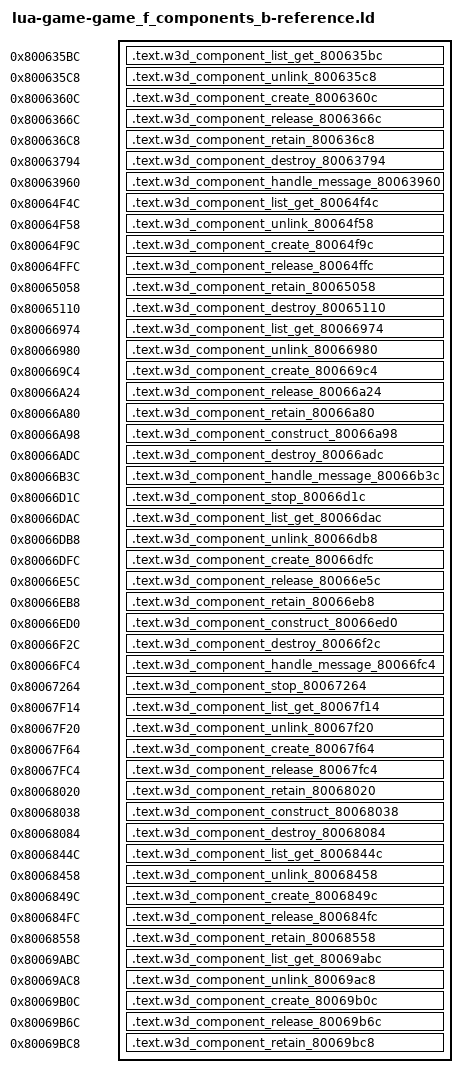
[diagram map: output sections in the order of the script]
/* Generated reference-only placements. All bodies are source-built. */
OUTPUT_FORMAT("elf32-powerpc")
OUTPUT_ARCH(powerpc)
ENTRY(w3d_component_list_get_800635bc)
_SDA_BASE_ = 0x804b2540;
_SDA2_BASE_ = 0x804c2540;
w3d_actor_base_destroy = 0x80161050;
w3d_actor_base_initialize = 0x80161014;
w3d_base_construct_8015fef0 = 0x8015fef0;
w3d_base_destroy_8015ff2c = 0x8015ff2c;
w3d_base_handle_message_8015fb34 = 0x8015fb34;
w3d_component_construct_800636e0 = 0x800636e0;
w3d_component_construct_80065070 = 0x80065070;
w3d_component_construct_80068570 = 0x80068570;
w3d_component_construct_80069c8c = 0x80069c8c;
w3d_component_destroy_80068648 = 0x80068648;
w3d_component_destroy_80069e94 = 0x80069e94;
w3d_component_list_80360300 = 0x80360300;
w3d_component_list_80360330 = 0x80360330;
w3d_component_list_80360360 = 0x80360360;
w3d_component_list_80360390 = 0x80360390;
w3d_component_list_803603c0 = 0x803603c0;
w3d_component_list_803603f0 = 0x803603f0;
w3d_component_list_80360420 = 0x80360420;
w3d_component_start_80063a0c = 0x80063a0c;
w3d_component_start_80066c9c = 0x80066c9c;
w3d_component_start_800670e0 = 0x800670e0;
w3d_component_stop_80064104 = 0x80064104;
w3d_component_vtable_8040edc0 = 0x8040edc0;
w3d_component_vtable_8040ee00 = 0x8040ee00;
w3d_component_vtable_8040ee40 = 0x8040ee40;
w3d_component_vtable_8040ee80 = 0x8040ee80;
w3d_component_vtable_8040eee8 = 0x8040eee8;
w3d_heap_allocate_entry_a = 0x801fe1d8;
w3d_owner_list_remove = 0x8020fd2c;
w3d_state_register = 0x8020fd04;
SECTIONS {
  .text.w3d_component_list_get_800635bc 0x800635bc : { *(.text.w3d_component_list_get_800635bc) }
  .text.w3d_component_unlink_800635c8 0x800635c8 : { *(.text.w3d_component_unlink_800635c8) }
  .text.w3d_component_create_8006360c 0x8006360c : { *(.text.w3d_component_create_8006360c) }
  .text.w3d_component_release_8006366c 0x8006366c : { *(.text.w3d_component_release_8006366c) }
  .text.w3d_component_retain_800636c8 0x800636c8 : { *(.text.w3d_component_retain_800636c8) }
  .text.w3d_component_destroy_80063794 0x80063794 : { *(.text.w3d_component_destroy_80063794) }
  .text.w3d_component_handle_message_80063960 0x80063960 : { *(.text.w3d_component_handle_message_80063960) }
  .text.w3d_component_list_get_80064f4c 0x80064f4c : { *(.text.w3d_component_list_get_80064f4c) }
  .text.w3d_component_unlink_80064f58 0x80064f58 : { *(.text.w3d_component_unlink_80064f58) }
  .text.w3d_component_create_80064f9c 0x80064f9c : { *(.text.w3d_component_create_80064f9c) }
  .text.w3d_component_release_80064ffc 0x80064ffc : { *(.text.w3d_component_release_80064ffc) }
  .text.w3d_component_retain_80065058 0x80065058 : { *(.text.w3d_component_retain_80065058) }
  .text.w3d_component_destroy_80065110 0x80065110 : { *(.text.w3d_component_destroy_80065110) }
  .text.w3d_component_list_get_80066974 0x80066974 : { *(.text.w3d_component_list_get_80066974) }
  .text.w3d_component_unlink_80066980 0x80066980 : { *(.text.w3d_component_unlink_80066980) }
  .text.w3d_component_create_800669c4 0x800669c4 : { *(.text.w3d_component_create_800669c4) }
  .text.w3d_component_release_80066a24 0x80066a24 : { *(.text.w3d_component_release_80066a24) }
  .text.w3d_component_retain_80066a80 0x80066a80 : { *(.text.w3d_component_retain_80066a80) }
  .text.w3d_component_construct_80066a98 0x80066a98 : { *(.text.w3d_component_construct_80066a98) }
  .text.w3d_component_destroy_80066adc 0x80066adc : { *(.text.w3d_component_destroy_80066adc) }
  .text.w3d_component_handle_message_80066b3c 0x80066b3c : { *(.text.w3d_component_handle_message_80066b3c) }
  .text.w3d_component_stop_80066d1c 0x80066d1c : { *(.text.w3d_component_stop_80066d1c) }
  .text.w3d_component_list_get_80066dac 0x80066dac : { *(.text.w3d_component_list_get_80066dac) }
  .text.w3d_component_unlink_80066db8 0x80066db8 : { *(.text.w3d_component_unlink_80066db8) }
  .text.w3d_component_create_80066dfc 0x80066dfc : { *(.text.w3d_component_create_80066dfc) }
  .text.w3d_component_release_80066e5c 0x80066e5c : { *(.text.w3d_component_release_80066e5c) }
  .text.w3d_component_retain_80066eb8 0x80066eb8 : { *(.text.w3d_component_retain_80066eb8) }
  .text.w3d_component_construct_80066ed0 0x80066ed0 : { *(.text.w3d_component_construct_80066ed0) }
  .text.w3d_component_destroy_80066f2c 0x80066f2c : { *(.text.w3d_component_destroy_80066f2c) }
  .text.w3d_component_handle_message_80066fc4 0x80066fc4 : { *(.text.w3d_component_handle_message_80066fc4) }
  .text.w3d_component_stop_80067264 0x80067264 : { *(.text.w3d_component_stop_80067264) }
  .text.w3d_component_list_get_80067f14 0x80067f14 : { *(.text.w3d_component_list_get_80067f14) }
  .text.w3d_component_unlink_80067f20 0x80067f20 : { *(.text.w3d_component_unlink_80067f20) }
  .text.w3d_component_create_80067f64 0x80067f64 : { *(.text.w3d_component_create_80067f64) }
  .text.w3d_component_release_80067fc4 0x80067fc4 : { *(.text.w3d_component_release_80067fc4) }
  .text.w3d_component_retain_80068020 0x80068020 : { *(.text.w3d_component_retain_80068020) }
  .text.w3d_component_construct_80068038 0x80068038 : { *(.text.w3d_component_construct_80068038) }
  .text.w3d_component_destroy_80068084 0x80068084 : { *(.text.w3d_component_destroy_80068084) }
  .text.w3d_component_list_get_8006844c 0x8006844c : { *(.text.w3d_component_list_get_8006844c) }
  .text.w3d_component_unlink_80068458 0x80068458 : { *(.text.w3d_component_unlink_80068458) }
  .text.w3d_component_create_8006849c 0x8006849c : { *(.text.w3d_component_create_8006849c) }
  .text.w3d_component_release_800684fc 0x800684fc : { *(.text.w3d_component_release_800684fc) }
  .text.w3d_component_retain_80068558 0x80068558 : { *(.text.w3d_component_retain_80068558) }
  .text.w3d_component_list_get_80069abc 0x80069abc : { *(.text.w3d_component_list_get_80069abc) }
  .text.w3d_component_unlink_80069ac8 0x80069ac8 : { *(.text.w3d_component_unlink_80069ac8) }
  .text.w3d_component_create_80069b0c 0x80069b0c : { *(.text.w3d_component_create_80069b0c) }
  .text.w3d_component_release_80069b6c 0x80069b6c : { *(.text.w3d_component_release_80069b6c) }
  .text.w3d_component_retain_80069bc8 0x80069bc8 : { *(.text.w3d_component_retain_80069bc8) }
  /DISCARD/ : { *(.text*) *(.rodata*) *(.data*) *(.bss*) *(.sdata*) *(.sbss*) *(.comment) }
}
